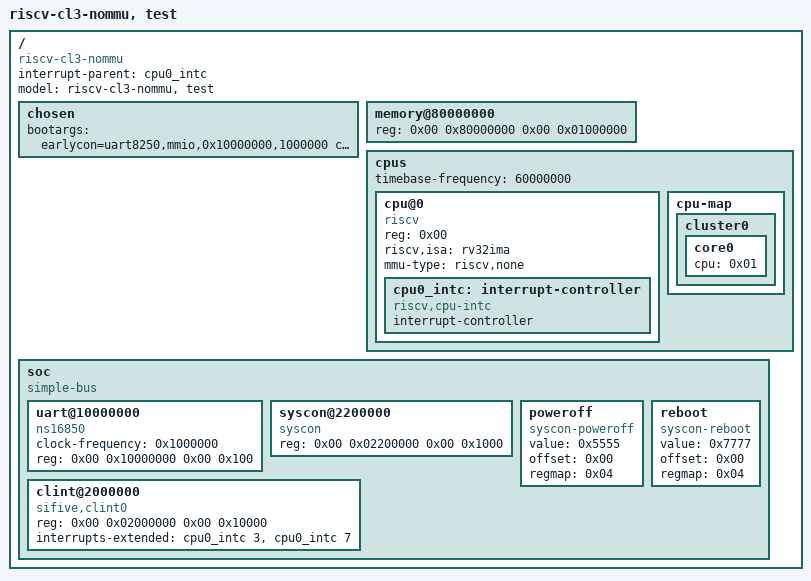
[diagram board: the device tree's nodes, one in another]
/dts-v1/;

/ {
	#address-cells = <0x02>;
	#size-cells = <0x02>;
	interrupt-parent = <&cpu0_intc>;
	compatible = "riscv-cl3-nommu";
	model = "riscv-cl3-nommu, test";

	chosen {
		bootargs = "earlycon=uart8250,mmio,0x10000000,1000000 console=ttyS0";
	};

	memory@80000000 {
		device_type = "memory";
		reg = <0x00 0x80000000 0x00 0x01000000>;
	};

	cpus {
		#address-cells = <0x01>;
		#size-cells = <0x00>;
		timebase-frequency = <60000000>;

		cpu@0 {
			phandle = <0x01>;
			device_type = "cpu";
			reg = <0x00>;
			status = "okay";
			compatible = "riscv";
			riscv,isa = "rv32ima";
			mmu-type = "riscv,none";

            cpu0_intc: interrupt-controller {
                compatible         = "riscv,cpu-intc";
                interrupt-controller;
                #address-cells     = <0>;
                #interrupt-cells   = <1>;
            };
		};

		cpu-map {

			cluster0 {

				core0 {
					cpu = <0x01>;
				};
			};
		};
	};

	soc {
		#address-cells = <0x02>;
		#size-cells = <0x02>;
		compatible = "simple-bus";
		ranges;

		uart@10000000 {
			clock-frequency = <0x1000000>;
			reg = <0x00 0x10000000 0x00 0x100>;
			compatible = "ns16850";
		};

		syscon@2200000 {
			phandle = <0x04>;
			reg = <0x00 0x02200000 0x00 0x1000>;
			compatible = "syscon";
		};

		poweroff {
			value = <0x5555>;
			offset = <0x00>;
			regmap = <0x04>;
			compatible = "syscon-poweroff";
		};

		reboot {
			value = <0x7777>;
			offset = <0x00>;
			regmap = <0x04>;
			compatible = "syscon-reboot";
		};



		clint@2000000 {
			compatible = "sifive,clint0", "riscv,clint0";
			reg = <0x00 0x02000000 0x00 0x10000>;
			interrupts-extended = <&cpu0_intc 3 &cpu0_intc 7>;
		};
	};
};
